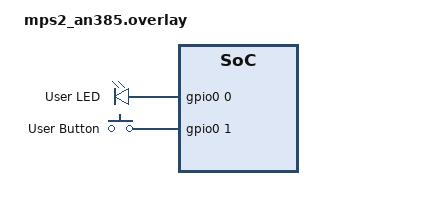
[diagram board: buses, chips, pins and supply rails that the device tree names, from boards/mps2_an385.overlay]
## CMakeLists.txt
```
cmake_minimum_required(VERSION 3.20.0)
find_package(Zephyr REQUIRED HINTS $ENV{ZEPHYR_BASE})
project(base_sample)

target_sources(app PRIVATE 
    src/main.c
    src/geradora.c
    src/filtro.c
    src/processadora.c
    src/sntp_client.c
    src/logger_module.c
    src/app_module.c
)
```

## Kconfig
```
menu "Zephyr"
source "Kconfig.zephyr"
endmenu

config LED_PIN
    int "GPIO pin number for LED"
    default 2
    help
      GPIO pin number for controlling the LED

config BUTTON_PIN
    int "GPIO pin number for Button"
    default 3
    help
      GPIO pin number for the button input

config PWM_DUTY_CYCLE_MIN
    int "Minimum PWM duty cycle"
    default 0
    help
      Minimum PWM duty cycle value (0-100)

config PWM_DUTY_CYCLE_MAX
    int "Maximum PWM duty cycle"
    default 100
    help
      Maximum PWM duty cycle value (0-100)

config PWM_FADE_STEP
    int "PWM fade step"
    default 5
    help
      Step value for PWM fade effect (1-100)

menu "SNTP Configuration"

config SNTP_SERVER
    string "SNTP server hostname"
    default "pool.ntp.org"
    help
      Hostname or IP address of the SNTP server to use for time synchronization.
      Examples: pool.ntp.org, time.google.com, 192.0.2.2

config SNTP_SYNC_INTERVAL
    int "SNTP synchronization interval (seconds)"
    default 60
    range 10 3600
    help
      Interval in seconds between SNTP synchronization attempts.
      Minimum: 10 seconds, Maximum: 3600 seconds (1 hour)

endmenu
```

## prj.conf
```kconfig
# Enable logging
CONFIG_LOG=y
CONFIG_LOG_MODE_IMMEDIATE=y
CONFIG_LOG_DEFAULT_LEVEL=3

# Enable GPIO
CONFIG_GPIO=y

# Enable GPIO pins
CONFIG_GPIO_INIT_PRIORITY=40

# Enable random number generator
CONFIG_TEST_RANDOM_GENERATOR=y

# ZBus (Event Bus)
CONFIG_ZBUS=y
CONFIG_ZBUS_PRIORITY_BOOST=y

# POSIX API for time functions
CONFIG_POSIX_API=y

# Increased stack sizes
CONFIG_MAIN_STACK_SIZE=2048
```

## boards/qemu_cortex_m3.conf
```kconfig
# Board configuration for QEMU Cortex-M3
# Network disabled for simplified testing
```

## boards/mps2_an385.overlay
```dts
#include <zephyr/dt-bindings/gpio/gpio.h>

/ {
    leds {
        compatible = "gpio-leds";
        led0: led {
            gpios = <&gpio0 0 GPIO_ACTIVE_HIGH>;
            label = "User LED";
        };
    };

    gpio_keys {
        compatible = "gpio-keys";
        button0: button {
            gpios = <&gpio0 1 0>;
            label = "User Button";
        };
    };

    aliases {
        led0 = &led0;
        sw0 = &button0;
    };
};
```

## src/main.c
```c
#include <zephyr/kernel.h>
#include <zephyr/logging/log.h>
#include "common.h"
#include "geradora.h"
#include "filtro.h"
#include "processadora.h"
#include "time_common.h"
#include "sntp_client.h"
#include "logger_module.h"
#include "app_module.h"

LOG_MODULE_REGISTER(main, LOG_LEVEL_INF);

// Buffers para as filas
char __aligned(4) input_msgq_buffer[MAX_QUEUE_SIZE * sizeof(struct sensor_data)];
char __aligned(4) output_msgq_buffer[MAX_QUEUE_SIZE * sizeof(struct sensor_data)];

// Definição das filas
struct k_msgq input_msgq;
struct k_msgq output_msgq;

void main(void)
{
    LOG_INF("===========================================");
    LOG_INF("Sistema Embarcado - Atividade 04");
    LOG_INF("SNTP + ZBus - Sincronização de Tempo");
    LOG_INF("===========================================");

    // Inicializa as filas de mensagens (sistema da atividade 03)
    k_msgq_init(&input_msgq, input_msgq_buffer, sizeof(struct sensor_data), 10);
    k_msgq_init(&output_msgq, output_msgq_buffer, sizeof(struct sensor_data), 10);

    LOG_INF("Inicializando threads do sistema de sensores...");

    // Cria thread do sensor de temperatura
    k_thread_create(&temp_thread,
                   temp_stack_area,
                   K_THREAD_STACK_SIZEOF(temp_stack_area),
                   temp_thread_entry,
                   NULL, NULL, NULL,
                   THREAD_PRIORITY,
                   0,
                   K_NO_WAIT);

    // Cria thread do sensor de umidade
    k_thread_create(&humid_thread,
                   humid_stack_area,
                   K_THREAD_STACK_SIZEOF(humid_stack_area),
                   humid_thread_entry,
                   NULL, NULL, NULL,
                   THREAD_PRIORITY,
                   0,
                   K_NO_WAIT);

    // Cria thread do filtro
    k_thread_create(&filter_thread,
                   filter_stack_area,
                   K_THREAD_STACK_SIZEOF(filter_stack_area),
                   filter_thread_entry,
                   NULL, NULL, NULL,
                   THREAD_PRIORITY,
                   0,
                   K_NO_WAIT);

    // Cria thread consumidora
    k_thread_create(&consumer_thread,
                   consumer_stack_area,
                   K_THREAD_STACK_SIZEOF(consumer_stack_area),
                   consumer_thread_entry,
                   NULL, NULL, NULL,
                   THREAD_PRIORITY,
                   0,
                   K_NO_WAIT);

    LOG_INF("Inicializando threads do sistema SNTP/ZBus...");

    // Cria thread do cliente SNTP
    k_thread_create(&sntp_thread,
                   sntp_stack_area,
                   K_THREAD_STACK_SIZEOF(sntp_stack_area),
                   sntp_client_entry,
                   NULL, NULL, NULL,
                   SNTP_PRIORITY,
                   0,
                   K_NO_WAIT);

    // Cria thread do Logger
    k_thread_create(&logger_thread,
                   logger_stack_area,
                   K_THREAD_STACK_SIZEOF(logger_stack_area),
                   logger_entry,
                   NULL, NULL, NULL,
                   LOGGER_PRIORITY,
                   0,
                   K_NO_WAIT);

    // Cria thread da Application
    k_thread_create(&app_thread,
                   app_stack_area,
                   K_THREAD_STACK_SIZEOF(app_stack_area),
                   app_entry,
                   NULL, NULL, NULL,
                   APP_PRIORITY,
                   0,
                   K_NO_WAIT);

    LOG_INF("Todas as threads iniciadas com sucesso!");
    LOG_INF("===========================================");
}
```

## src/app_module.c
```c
#include <zephyr/kernel.h>
#include <zephyr/logging/log.h>
#include <time.h>
#include "time_common.h"
#include "app_module.h"

LOG_MODULE_REGISTER(app_module, LOG_LEVEL_INF);

// Definição da thread e stack
K_THREAD_STACK_DEFINE(app_stack_area, APP_STACK_SIZE);
struct k_thread app_thread;

// Armazenamento de timestamps de eventos
static int64_t last_event_timestamp = 0;
static int64_t current_timestamp = 0;
static bool time_available = false;

/**
 * @brief Callback chamado quando nova mensagem de tempo é recebida
 */
static void app_time_callback(const struct zbus_channel *chan)
{
    const struct time_msg *msg = zbus_chan_const_msg(chan);
    
    if (msg->is_synchronized) {
        int64_t previous_timestamp = current_timestamp;
        current_timestamp = msg->timestamp;
        time_available = true;
        
        LOG_INF("=== APPLICATION EVENT ===");
        LOG_INF("Horário recebido: %04d-%02d-%02d %02d:%02d:%02d UTC",
                msg->time_info.tm_year + 1900,
                msg->time_info.tm_mon + 1,
                msg->time_info.tm_mday,
                msg->time_info.tm_hour,
                msg->time_info.tm_min,
                msg->time_info.tm_sec);
        
        if (previous_timestamp > 0) {
            int64_t time_diff = current_timestamp - previous_timestamp;
            LOG_INF("Tempo desde última atualização: %lld segundos", time_diff);
        }
        
        if (last_event_timestamp > 0) {
            int64_t event_diff = current_timestamp - last_event_timestamp;
            LOG_INF("Tempo desde último evento processado: %lld segundos", event_diff);
        }
        
        LOG_INF("========================");
    }
}

// Definir listener para o canal de tempo
ZBUS_LISTENER_DEFINE(app_listener, app_time_callback);

// Adicionar observer ao canal
ZBUS_CHAN_ADD_OBS(time_channel, app_listener, 0);

/**
 * @brief Simula processamento de evento da aplicação
 */
static void process_application_event(void)
{
    if (!time_available) {
        LOG_WRN("Tentativa de processar evento sem tempo sincronizado");
        return;
    }
    
    last_event_timestamp = current_timestamp;
    
    LOG_INF(">>> Evento da aplicação processado");
    LOG_INF(">>> Timestamp do evento: %lld", last_event_timestamp);
    
    // Aqui você pode adicionar lógica de aplicação real
    // Por exemplo: controle de eventos baseado em tempo,
    // agendamento de tarefas, etc.
}

/**
 * @brief Entry point da thread Application
 */
void app_entry(void *p1, void *p2, void *p3)
{
    ARG_UNUSED(p1);
    ARG_UNUSED(p2);
    ARG_UNUSED(p3);

    LOG_INF("Thread Application iniciada");
    LOG_INF("Aguardando sincronização de tempo...");

    int event_counter = 0;

    while (1) {
        // Aguardar um período
        k_sleep(K_SECONDS(30));
        
        if (time_available) {
            // Simular processamento de evento periódico
            event_counter++;
            LOG_INF("Processando evento periódico #%d", event_counter);
            process_application_event();
            
            // Calcular próximo evento
            if (current_timestamp > 0) {
                LOG_INF("Próximo evento agendado para daqui a 30 segundos");
            }
        } else {
            LOG_WRN("Aguardando sincronização de tempo para processar eventos");
        }
    }
}
```

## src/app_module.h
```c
#ifndef APP_MODULE_H
#define APP_MODULE_H

#include <zephyr/kernel.h>

/**
 * @brief Entry point da thread Application
 * 
 * Esta thread subscreve ao time_channel e calcula
 * intervalos de tempo entre eventos
 */
void app_entry(void *p1, void *p2, void *p3);

/**
 * @brief Declaração da thread e stack
 */
extern struct k_thread app_thread;
extern K_THREAD_STACK_DEFINE(app_stack_area, APP_STACK_SIZE);

#endif /* APP_MODULE_H */
```

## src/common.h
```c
#ifndef COMMON_H
#define COMMON_H

#include <zephyr/kernel.h>

// Definições de faixas válidas
#define TEMP_MIN 18
#define TEMP_MAX 30
#define UMID_MIN 40
#define UMID_MAX 70

// Tamanho das filas
#define MAX_QUEUE_SIZE 10
#define STACK_SIZE 1024
#define THREAD_PRIORITY 7

// Tipos de dados
enum sensor_type {
    SENSOR_TEMP,
    SENSOR_UMID
};

// Estrutura da mensagem
struct sensor_data {
    enum sensor_type type;
    int value;
    uint32_t timestamp;
};

// Declaração externa das filas
extern struct k_msgq input_msgq;
extern struct k_msgq output_msgq;

#endif /* COMMON_H */
```

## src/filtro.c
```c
#include <zephyr/kernel.h>
#include "common.h"
#include "filtro.h"

// Define stack para a thread
K_THREAD_STACK_DEFINE(filter_stack_area, STACK_SIZE);

// Estrutura da thread
struct k_thread filter_thread;

// Verifica se o valor está dentro da faixa válida
static bool is_value_valid(enum sensor_type type, int value)
{
    switch (type) {
        case SENSOR_TEMP:
            return (value >= TEMP_MIN && value <= TEMP_MAX);
        case SENSOR_UMID:
            return (value >= UMID_MIN && value <= UMID_MAX);
        default:
            return false;
    }
}

// Thread de filtragem
void filter_thread_entry(void *p1, void *p2, void *p3)
{
    struct sensor_data data;

    while (1) {
        // Aguarda dados na fila de entrada
        k_msgq_get(&input_msgq, &data, K_FOREVER);

        // Valida os dados
        if (is_value_valid(data.type, data.value)) {
            // Dados válidos: envia para fila de saída
            if (k_msgq_put(&output_msgq, &data, K_NO_WAIT) != 0) {
                printk("Fila de saída cheia, descartando dado válido\n");
            }
        } else {
            // Dados inválidos: registra no log
            printk("Dado inválido: tipo=%d, valor=%d, timestamp=%u\n",
                   data.type, data.value, data.timestamp);
        }

        k_sleep(K_MSEC(100));  // Evita sobrecarregar o sistema
    }
}
```

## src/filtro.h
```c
#ifndef FILTRO_H
#define FILTRO_H

#include <zephyr/kernel.h>

// Thread stack
#define STACK_SIZE 1024
extern K_THREAD_STACK_DEFINE(filter_stack_area, STACK_SIZE);

// Thread data
extern struct k_thread filter_thread;

// Thread entry point
void filter_thread_entry(void *p1, void *p2, void *p3);

#endif /* FILTRO_H */
```

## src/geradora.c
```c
#include <zephyr/kernel.h>
#include <stdlib.h>
#include "common.h"
#include "geradora.h"

// Define stacks para as threads
K_THREAD_STACK_DEFINE(temp_stack_area, STACK_SIZE);
K_THREAD_STACK_DEFINE(humid_stack_area, STACK_SIZE);

// Estruturas das threads
struct k_thread temp_thread;
struct k_thread humid_thread;

// Simula leitura de sensor de temperatura
static int read_temperature(void)
{
    // Simula valores entre 15°C e 35°C
    return (rand() % 21) + 15;
}

// Simula leitura de sensor de umidade
static int read_humidity(void)
{
    // Simula valores entre 30% e 80%
    return (rand() % 51) + 30;
}

// Thread do sensor de temperatura
void temp_thread_entry(void *p1, void *p2, void *p3)
{
    struct sensor_data data;
    data.type = SENSOR_TEMP;

    while (1) {
        data.value = read_temperature();
        data.timestamp = k_uptime_get_32();

        if (k_msgq_put(&input_msgq, &data, K_NO_WAIT) != 0) {
            printk("Fila de entrada cheia, descartando leitura de temperatura\n");
        }

        k_sleep(K_SECONDS(2));
    }
}

// Thread do sensor de umidade
void humid_thread_entry(void *p1, void *p2, void *p3)
{
    struct sensor_data data;
    data.type = SENSOR_UMID;

    while (1) {
        data.value = read_humidity();
        data.timestamp = k_uptime_get_32();

        if (k_msgq_put(&input_msgq, &data, K_NO_WAIT) != 0) {
            printk("Fila de entrada cheia, descartando leitura de umidade\n");
        }

        k_sleep(K_SECONDS(2));
    }
}
```

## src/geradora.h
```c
#ifndef GERADORA_H
#define GERADORA_H

#include <zephyr/kernel.h>

// Thread stacks
#define STACK_SIZE 1024
extern K_THREAD_STACK_DEFINE(temp_stack_area, STACK_SIZE);
extern K_THREAD_STACK_DEFINE(humid_stack_area, STACK_SIZE);

// Thread data
extern struct k_thread temp_thread;
extern struct k_thread humid_thread;

// Thread entry points
void temp_thread_entry(void *p1, void *p2, void *p3);
void humid_thread_entry(void *p1, void *p2, void *p3);

#endif /* GERADORA_H */
```

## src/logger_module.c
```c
#include <zephyr/kernel.h>
#include <zephyr/logging/log.h>
#include <time.h>
#include "time_common.h"
#include "logger_module.h"

LOG_MODULE_REGISTER(logger_module, LOG_LEVEL_INF);

// Definição da thread e stack
K_THREAD_STACK_DEFINE(logger_stack_area, LOGGER_STACK_SIZE);
struct k_thread logger_thread;

// Relógio interno do logger
static struct tm internal_clock;
static bool clock_initialized = false;

/**
 * @brief Callback chamado quando nova mensagem de tempo é recebida
 */
static void time_msg_callback(const struct zbus_channel *chan)
{
    const struct time_msg *msg = zbus_chan_const_msg(chan);
    
    if (msg->is_synchronized) {
        // Atualizar relógio interno
        memcpy(&internal_clock, &msg->time_info, sizeof(struct tm));
        clock_initialized = true;
        
        // Registrar log com timestamp atualizado
        LOG_INF("=== LOG ENTRY ===");
        LOG_INF("Timestamp: %lld", msg->timestamp);
        LOG_INF("Data/Hora: %04d-%02d-%02d %02d:%02d:%02d UTC",
                internal_clock.tm_year + 1900,
                internal_clock.tm_mon + 1,
                internal_clock.tm_mday,
                internal_clock.tm_hour,
                internal_clock.tm_min,
                internal_clock.tm_sec);
        LOG_INF("Uptime: %lld ms", msg->uptime_ms);
        LOG_INF("Status: Relógio sincronizado com SNTP");
        LOG_INF("================");
    } else {
        LOG_WRN("Recebida mensagem de tempo não sincronizada");
        LOG_WRN("Uptime: %lld ms", msg->uptime_ms);
    }
}

// Definir listener para o canal de tempo
ZBUS_LISTENER_DEFINE(logger_listener, time_msg_callback);

// Adicionar observer ao canal
ZBUS_CHAN_ADD_OBS(time_channel, logger_listener, 0);

/**
 * @brief Entry point da thread Logger
 */
void logger_entry(void *p1, void *p2, void *p3)
{
    ARG_UNUSED(p1);
    ARG_UNUSED(p2);
    ARG_UNUSED(p3);

    LOG_INF("Thread Logger iniciada");
    LOG_INF("Aguardando sincronização de tempo...");

    // A thread pode fazer outras tarefas enquanto aguarda eventos ZBus
    // Os callbacks serão chamados automaticamente quando mensagens chegarem
    
    while (1) {
        if (clock_initialized) {
            // Pode fazer logging periódico ou outras operações
            // Por enquanto, apenas aguarda
        }
        
        // Sleep para reduzir uso de CPU
        k_sleep(K_SECONDS(10));
        
        if (clock_initialized) {
            LOG_DBG("Logger heartbeat - Clock: %02d:%02d:%02d",
                    internal_clock.tm_hour,
                    internal_clock.tm_min,
                    internal_clock.tm_sec);
        }
    }
}
```

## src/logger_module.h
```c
#ifndef LOGGER_MODULE_H
#define LOGGER_MODULE_H

#include <zephyr/kernel.h>

/**
 * @brief Entry point da thread Logger
 * 
 * Esta thread subscreve ao time_channel e registra
 * timestamps quando recebe atualizações
 */
void logger_entry(void *p1, void *p2, void *p3);

/**
 * @brief Declaração da thread e stack
 */
extern struct k_thread logger_thread;
extern K_THREAD_STACK_DEFINE(logger_stack_area, LOGGER_STACK_SIZE);

#endif /* LOGGER_MODULE_H */
```

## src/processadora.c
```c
#include <zephyr/kernel.h>
#include "common.h"
#include "processadora.h"

// Define stack para a thread
K_THREAD_STACK_DEFINE(consumer_stack_area, STACK_SIZE);

// Estrutura da thread
struct k_thread consumer_thread;

// Thread consumidora
void consumer_thread_entry(void *p1, void *p2, void *p3)
{
    struct sensor_data data;

    while (1) {
        // Aguarda dados na fila de saída
        k_msgq_get(&output_msgq, &data, K_FOREVER);

        // Processa os dados válidos
        switch (data.type) {
            case SENSOR_TEMP:
                printk("Temperatura válida: %d°C (timestamp: %u)\n",
                       data.value, data.timestamp);
                break;
            case SENSOR_UMID:
                printk("Umidade válida: %d%% (timestamp: %u)\n",
                       data.value, data.timestamp);
                break;
            default:
                printk("Tipo de sensor desconhecido\n");
                break;
        }

        k_sleep(K_MSEC(100));  // Evita sobrecarregar o sistema
    }
}
```

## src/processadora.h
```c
#ifndef PROCESSADORA_H
#define PROCESSADORA_H

#include <zephyr/kernel.h>

// Thread stack
#define STACK_SIZE 1024
extern K_THREAD_STACK_DEFINE(consumer_stack_area, STACK_SIZE);

// Thread data
extern struct k_thread consumer_thread;

// Thread entry point
void consumer_thread_entry(void *p1, void *p2, void *p3);

#endif /* PROCESSADORA_H */
```

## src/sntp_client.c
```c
#include <zephyr/kernel.h>
#include <zephyr/logging/log.h>
#include <time.h>
#include "time_common.h"
#include "sntp_client.h"

LOG_MODULE_REGISTER(sntp_client, LOG_LEVEL_DBG);

// Definição da thread e stack
K_THREAD_STACK_DEFINE(sntp_stack_area, SNTP_STACK_SIZE);
struct k_thread sntp_thread;

// Definição do canal ZBus para mensagens de tempo
ZBUS_CHAN_DEFINE(time_channel,
                 struct time_msg,
                 NULL,
                 NULL,
                 ZBUS_OBSERVERS_EMPTY,
                 ZBUS_MSG_INIT(0));

/**
 * @brief Simula sincronização SNTP e atualiza o relógio do sistema
 * 
 * @return 0 se sucesso, negativo em caso de erro
 */
static int sync_sntp_time(void)
{
    // Simular timestamp SNTP (2025-11-02 14:30:00 UTC)
    time_t simulated_time = 1730558400 + (k_uptime_get() / 1000);
    
    LOG_INF("Simulando sincronização SNTP com %s", SNTP_SERVER);

    // Atualizar relógio do sistema
    struct timespec ts;
    ts.tv_sec = simulated_time;
    ts.tv_nsec = 0;

    int ret = clock_settime(CLOCK_REALTIME, &ts);
    if (ret < 0) {
        LOG_ERR("Falha ao configurar relógio: %d", errno);
        return -errno;
    }

    LOG_INF("Sincronização SNTP bem-sucedida: %lld.%09ld",
            (long long)ts.tv_sec, ts.tv_nsec);

    return 0;
}

/**
 * @brief Entry point da thread SNTP Client
 */
void sntp_client_entry(void *p1, void *p2, void *p3)
{
    ARG_UNUSED(p1);
    ARG_UNUSED(p2);
    ARG_UNUSED(p3);

    struct time_msg msg;
    int ret;

    LOG_INF("Thread SNTP Client iniciada");
    LOG_INF("NOTA: Usando simulação de SNTP (sem rede real)");

    // Aguardar um pouco para o sistema estar pronto
    k_sleep(K_SECONDS(2));

    while (1) {
        // Simular sincronização com servidor SNTP
        ret = sync_sntp_time();
        
        if (ret == 0) {
            // Sincronização bem-sucedida, preparar mensagem
            struct timespec ts;
            clock_gettime(CLOCK_REALTIME, &ts);
            
            msg.timestamp = ts.tv_sec;
            msg.uptime_ms = k_uptime_get();
            msg.is_synchronized = true;
            
            // Converter para struct tm
            gmtime_r(&ts.tv_sec, &msg.time_info);
            
            // Publicar no canal ZBus
            ret = zbus_chan_pub(&time_channel, &msg, K_SECONDS(1));
            if (ret < 0) {
                LOG_ERR("Falha ao publicar no ZBus: %d", ret);
            } else {
                LOG_INF("Horário publicado: %04d-%02d-%02d %02d:%02d:%02d UTC",
                        msg.time_info.tm_year + 1900,
                        msg.time_info.tm_mon + 1,
                        msg.time_info.tm_mday,
                        msg.time_info.tm_hour,
                        msg.time_info.tm_min,
                        msg.time_info.tm_sec);
            }
        } else {
            LOG_WRN("Sincronização SNTP falhou, tentando novamente em breve");
            
            // Publicar mensagem indicando falha na sincronização
            msg.timestamp = 0;
            msg.uptime_ms = k_uptime_get();
            msg.is_synchronized = false;
            memset(&msg.time_info, 0, sizeof(struct tm));
        }

        // Aguardar intervalo antes da próxima sincronização
        k_sleep(K_SECONDS(SNTP_SYNC_INTERVAL));
    }
}
```
